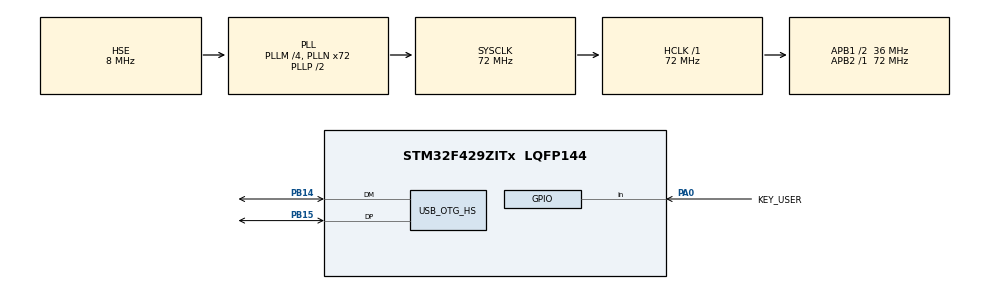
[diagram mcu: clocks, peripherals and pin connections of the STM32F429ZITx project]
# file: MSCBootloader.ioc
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Mcu.Family=STM32F4
Mcu.Name=STM32F429ZITx
Mcu.Package=LQFP144
NVIC.OTG_HS_IRQn=true\:0\:0\:false\:false\:true\:true
NVIC.PriorityGroup=NVIC_PRIORITYGROUP_4
PA0/WKUP.GPIO_Label=KEY_USER
PA0/WKUP.Signal=GPIO_Input
PA13.Mode=Serial_Wire
PA13.Signal=SYS_JTMS-SWDIO
PA14.Mode=Serial_Wire
PA14.Signal=SYS_JTCK-SWCLK
PB14.Mode=Device_Only_FS
PB14.Signal=USB_OTG_HS_DM
PB15.Mode=Device_Only_FS
PB15.Signal=USB_OTG_HS_DP
PH0/OSC_IN.Mode=HSE-External-Oscillator
PH0/OSC_IN.Signal=RCC_OSC_IN
PH1/OSC_OUT.Mode=HSE-External-Oscillator
PH1/OSC_OUT.Signal=RCC_OSC_OUT
ProjectManager.HeapSize=0x200
ProjectManager.StackSize=0x400
ProjectManager.TargetToolchain=SW4STM32
RCC.48MHZClocksFreq_Value=48000000
RCC.AHBFreq_Value=72000000
RCC.APB1CLKDivider=RCC_HCLK_DIV2
RCC.APB1Freq_Value=36000000
RCC.APB1TimFreq_Value=72000000
RCC.APB2Freq_Value=72000000
RCC.APB2TimFreq_Value=72000000
RCC.CortexFreq_Value=72000000
RCC.HCLKFreq_Value=72000000
RCC.HSE_VALUE=8000000
RCC.HSI_VALUE=16000000
RCC.LSE_VALUE=32768
RCC.PLLM=4
RCC.PLLN=72
RCC.PLLQ=3
RCC.SYSCLKFreq_VALUE=72000000
RCC.SYSCLKSource=RCC_SYSCLKSOURCE_PLLCLK
RCC.VCOOutputFreq_Value=144000000
USB_DEVICE.CLASS_NAME_HS=MSC
USB_DEVICE.VirtualMode-MSC_HS=Msc
USB_DEVICE.VirtualModeHS=Msc_HS
USB_OTG_HS.VirtualMode-Device_Only_FS=Device_Only_FS
VP_USB_DEVICE_VS_USB_DEVICE_MSC_HS.Mode=MSC_HS
board=custom

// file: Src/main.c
/**
  ******************************************************************************
  * @file           : main.c
  * @brief          : Main program body
  ******************************************************************************
  * This notice applies to any and all portions of this file
  * that are not between comment pairs USER CODE BEGIN and
  * USER CODE END. Other portions of this file, whether
  * inserted by the user or by software development tools
  * are owned by their respective copyright owners.
  *
  * Copyright (c) 2018 STMicroelectronics International N.V.
  * All rights reserved.
  *
  * Redistribution and use in source and binary forms, with or without
  * modification, are permitted, provided that the following conditions are met:
  *
  * 1. Redistribution of source code must retain the above copyright notice,
  *    this list of conditions and the following disclaimer.
  * 2. Redistributions in binary form must reproduce the above copyright notice,
  *    this list of conditions and the following disclaimer in the documentation
  *    and/or other materials provided with the distribution.
  * 3. Neither the name of STMicroelectronics nor the names of other
  *    contributors to this software may be used to endorse or promote products
  *    derived from this software without specific written permission.
  * 4. This software, including modifications and/or derivative works of this
  *    software, must execute solely and exclusively on microcontroller or
  *    microprocessor devices manufactured by or for STMicroelectronics.
  * 5. Redistribution and use of this software other than as permitted under
  *    this license is void and will automatically terminate your rights under
  *    this license.
  *
  * THIS SOFTWARE IS PROVIDED BY STMICROELECTRONICS AND CONTRIBUTORS "AS IS"
  * AND ANY EXPRESS, IMPLIED OR STATUTORY WARRANTIES, INCLUDING, BUT NOT
  * LIMITED TO, THE IMPLIED WARRANTIES OF MERCHANTABILITY, FITNESS FOR A
  * PARTICULAR PURPOSE AND NON-INFRINGEMENT OF THIRD PARTY INTELLECTUAL PROPERTY
  * RIGHTS ARE DISCLAIMED TO THE FULLEST EXTENT PERMITTED BY LAW. IN NO EVENT
  * SHALL STMICROELECTRONICS OR CONTRIBUTORS BE LIABLE FOR ANY DIRECT, INDIRECT,
  * INCIDENTAL, SPECIAL, EXEMPLARY, OR CONSEQUENTIAL DAMAGES (INCLUDING, BUT NOT
  * LIMITED TO, PROCUREMENT OF SUBSTITUTE GOODS OR SERVICES; LOSS OF USE, DATA,
  * OR PROFITS; OR BUSINESS INTERRUPTION) HOWEVER CAUSED AND ON ANY THEORY OF
  * LIABILITY, WHETHER IN CONTRACT, STRICT LIABILITY, OR TORT (INCLUDING
  * NEGLIGENCE OR OTHERWISE) ARISING IN ANY WAY OUT OF THE USE OF THIS SOFTWARE,
  * EVEN IF ADVISED OF THE POSSIBILITY OF SUCH DAMAGE.
  *
  ******************************************************************************
  */
#include "main.h"
#include "stm32f4xx_hal.h"
#include "usb_device.h"
#include "gpio.h"

/* USER CODE BEGIN Includes */
#include "bootloader.h"
#include "pfs.h"
/* USER CODE END Includes */

/* USER CODE BEGIN PV */
/* Private variables ---------------------------------------------------------*/

/* USER CODE END PV */

void SystemClock_Config(void);

/* USER CODE BEGIN PFP */
/* Private function prototypes -----------------------------------------------*/

extern void SCSI_ProcessReadCompleted(USBD_HandleTypeDef  *pdev, const uint8_t *buffer, uint16_t length);
extern void SCSI_ProcessWriteCompleted(USBD_HandleTypeDef  *pdev);

/* USER CODE END PFP */

int main(void)
{

  /* MCU Configuration----------------------------------------------------------*/

  /* Reset of all peripherals, Initializes the Flash interface and the Systick. */
  HAL_Init();

  /* Configure the system clock */
  SystemClock_Config();

  /* Initialize all configured peripherals */
  MX_GPIO_Init();
  /* USER CODE BEGIN 2 */
  bootloaderInit();
  MX_USB_DEVICE_Init();
  /* USER CODE END 2 */

  /* Infinite loop */
  /* USER CODE BEGIN WHILE */
  while (1)
  {
    pfsProcessLongOps();

  /* USER CODE END WHILE */

  }

}

void SystemClock_Config(void)
{

  RCC_OscInitTypeDef RCC_OscInitStruct;
  RCC_ClkInitTypeDef RCC_ClkInitStruct;

    /**Configure the main internal regulator output voltage
    */
  __HAL_RCC_PWR_CLK_ENABLE();

  __HAL_PWR_VOLTAGESCALING_CONFIG(PWR_REGULATOR_VOLTAGE_SCALE3);

    /**Initializes the CPU, AHB and APB busses clocks
    */
  RCC_OscInitStruct.OscillatorType = RCC_OSCILLATORTYPE_HSE;
  RCC_OscInitStruct.HSEState = RCC_HSE_ON;
  RCC_OscInitStruct.PLL.PLLState = RCC_PLL_ON;
  RCC_OscInitStruct.PLL.PLLSource = RCC_PLLSOURCE_HSE;
  RCC_OscInitStruct.PLL.PLLM = 4;
  RCC_OscInitStruct.PLL.PLLN = 72;
  RCC_OscInitStruct.PLL.PLLP = RCC_PLLP_DIV2;
  RCC_OscInitStruct.PLL.PLLQ = 3;
  if (HAL_RCC_OscConfig(&RCC_OscInitStruct) != HAL_OK)
  {
    _Error_Handler(__FILE__, __LINE__);
  }

    /**Initializes the CPU, AHB and APB busses clocks
    */
  RCC_ClkInitStruct.ClockType = RCC_CLOCKTYPE_HCLK|RCC_CLOCKTYPE_SYSCLK
                              |RCC_CLOCKTYPE_PCLK1|RCC_CLOCKTYPE_PCLK2;
  RCC_ClkInitStruct.SYSCLKSource = RCC_SYSCLKSOURCE_PLLCLK;
  RCC_ClkInitStruct.AHBCLKDivider = RCC_SYSCLK_DIV1;
  RCC_ClkInitStruct.APB1CLKDivider = RCC_HCLK_DIV2;
  RCC_ClkInitStruct.APB2CLKDivider = RCC_HCLK_DIV1;

  if (HAL_RCC_ClockConfig(&RCC_ClkInitStruct, FLASH_LATENCY_2) != HAL_OK)
  {
    _Error_Handler(__FILE__, __LINE__);
  }

    /**Configure the Systick interrupt time
    */
  HAL_SYSTICK_Config(HAL_RCC_GetHCLKFreq()/1000);

    /**Configure the Systick
    */
  HAL_SYSTICK_CLKSourceConfig(SYSTICK_CLKSOURCE_HCLK);

  /* SysTick_IRQn interrupt configuration */
  HAL_NVIC_SetPriority(SysTick_IRQn, 0, 0);
}

/* USER CODE BEGIN 4 */

bool bootloaderIsFirmwarePresent(void)
{
  uint32_t *pEStack = (uint32_t *)BOOTLOADER_FW_AREA_START;
  uint32_t estack = *pEStack;

  if ((estack >= 0x20000000) && (estack <= (0x20000000 + (192 * 1024)))) {
    return true;
  }

  return false;
}

bool bootloaderIsManualStartRequired(void)
{
  if (HAL_GPIO_ReadPin(KEY_USER_GPIO_Port, KEY_USER_Pin) == GPIO_PIN_SET) {
    return true;
  }

  return false;
}

void bootloaderRunFirmware(void)
{
  typedef void (*pFunction)(void);
  pFunction Jump_To_Application;
  volatile uint32_t *vectorsTable = (volatile uint32_t *)BOOTLOADER_FW_AREA_START;

  uint32_t JumpAddress = vectorsTable[1];
  Jump_To_Application = (pFunction) JumpAddress;

  /* Initialize user application's Stack Pointer */
  __set_MSP(vectorsTable[0]);
  Jump_To_Application();
}

static uint32_t GetSector(uint32_t Address);
static uint32_t GetSectorSize(uint32_t Sector);

bool bootloaderPrepareFimrwareArea(void)
{
  HAL_FLASH_Unlock();

  uint32_t count = BOOTLOADER_FW_AREA_SIZE / sizeof(uint32_t);
  uint32_t *p = (uint32_t *)BOOTLOADER_FW_AREA_START;

  for (uint32_t i = 0 ; i < count; i++) {
    if (*p++ != 0) {
      FLASH_EraseInitTypeDef EraseInitStruct;
      uint32_t FirstSector = 0, NbOfSectors = 0;
      uint32_t Address = 0, SECTORError = 0;

      /* Get the 1st sector to erase */
      FirstSector = GetSector(BOOTLOADER_FW_AREA_START);
      /* Get the number of sector to erase from 1st sector*/
      NbOfSectors = GetSector(BOOTLOADER_FW_AREA_START + BOOTLOADER_FW_AREA_SIZE - 1) - FirstSector + 1;
      EraseInitStruct.TypeErase     = FLASH_TYPEERASE_SECTORS;
      EraseInitStruct.VoltageRange  = FLASH_VOLTAGE_RANGE_3;
      EraseInitStruct.Sector        = FirstSector;
      EraseInitStruct.NbSectors     = NbOfSectors;

      if (HAL_FLASHEx_Erase(&EraseInitStruct, &SECTORError) != HAL_OK) {
        while (1) {
          __NOP();
        }
      }

      break;
    }
  }

  return true;
}

void pfsFileReadCompletedCallback(void *context, const uint8_t *buffer, uint16_t length)
{
  SCSI_ProcessReadCompleted((USBD_HandleTypeDef *)context, buffer, length);
}

void pfsFileWriteCompletedCallback(void *context)
{
  SCSI_ProcessWriteCompleted((USBD_HandleTypeDef *)context);
}

bool bootloaderWriteFirmware(const uint8_t *buffer, uint32_t address, uint32_t count)
{
  for (uint32_t itemIndex = 0u; itemIndex < count; itemIndex += 4u) {
    const uint32_t *value = (const uint32_t *)&buffer[itemIndex];

    if (HAL_FLASH_Program(FLASH_TYPEPROGRAM_WORD, address + itemIndex, (*value)) != HAL_OK) {
      return false;
    }
  }

  return true;
}

#define ADDR_FLASH_SECTOR_0     ((uint32_t)0x08000000) /* Base @ of Sector 0, 16 Kbytes */
#define ADDR_FLASH_SECTOR_1     ((uint32_t)0x08004000) /* Base @ of Sector 1, 16 Kbytes */
#define ADDR_FLASH_SECTOR_2     ((uint32_t)0x08008000) /* Base @ of Sector 2, 16 Kbytes */
#define ADDR_FLASH_SECTOR_3     ((uint32_t)0x0800C000) /* Base @ of Sector 3, 16 Kbytes */
#define ADDR_FLASH_SECTOR_4     ((uint32_t)0x08010000) /* Base @ of Sector 4, 64 Kbytes */
#define ADDR_FLASH_SECTOR_5     ((uint32_t)0x08020000) /* Base @ of Sector 5, 128 Kbytes */
#define ADDR_FLASH_SECTOR_6     ((uint32_t)0x08040000) /* Base @ of Sector 6, 128 Kbytes */
#define ADDR_FLASH_SECTOR_7     ((uint32_t)0x08060000) /* Base @ of Sector 7, 128 Kbytes */
#define ADDR_FLASH_SECTOR_8     ((uint32_t)0x08080000) /* Base @ of Sector 8, 128 Kbytes */
#define ADDR_FLASH_SECTOR_9     ((uint32_t)0x080A0000) /* Base @ of Sector 9, 128 Kbytes */
#define ADDR_FLASH_SECTOR_10    ((uint32_t)0x080C0000) /* Base @ of Sector 10, 128 Kbytes */
#define ADDR_FLASH_SECTOR_11    ((uint32_t)0x080E0000) /* Base @ of Sector 11, 128 Kbytes */

/* Base address of the Flash sectors Bank 2 */
#define ADDR_FLASH_SECTOR_12     ((uint32_t)0x08100000) /* Base @ of Sector 0, 16 Kbytes */
#define ADDR_FLASH_SECTOR_13     ((uint32_t)0x08104000) /* Base @ of Sector 1, 16 Kbytes */
#define ADDR_FLASH_SECTOR_14     ((uint32_t)0x08108000) /* Base @ of Sector 2, 16 Kbytes */
#define ADDR_FLASH_SECTOR_15     ((uint32_t)0x0810C000) /* Base @ of Sector 3, 16 Kbytes */
#define ADDR_FLASH_SECTOR_16     ((uint32_t)0x08110000) /* Base @ of Sector 4, 64 Kbytes */
#define ADDR_FLASH_SECTOR_17     ((uint32_t)0x08120000) /* Base @ of Sector 5, 128 Kbytes */
#define ADDR_FLASH_SECTOR_18     ((uint32_t)0x08140000) /* Base @ of Sector 6, 128 Kbytes */
#define ADDR_FLASH_SECTOR_19     ((uint32_t)0x08160000) /* Base @ of Sector 7, 128 Kbytes */
#define ADDR_FLASH_SECTOR_20     ((uint32_t)0x08180000) /* Base @ of Sector 8, 128 Kbytes  */
#define ADDR_FLASH_SECTOR_21     ((uint32_t)0x081A0000) /* Base @ of Sector 9, 128 Kbytes  */
#define ADDR_FLASH_SECTOR_22     ((uint32_t)0x081C0000) /* Base @ of Sector 10, 128 Kbytes */
#define ADDR_FLASH_SECTOR_23     ((uint32_t)0x081E0000) /* Base @ of Sector 11, 128 Kbytes */

/**
  * @brief  Gets the sector of a given address
  * @param  None
  * @retval The sector of a given address
  */
static uint32_t GetSector(uint32_t Address)
{
  uint32_t sector = 0;

  if ((Address < ADDR_FLASH_SECTOR_1) && (Address >= ADDR_FLASH_SECTOR_0)) {
    sector = FLASH_SECTOR_0;
  } else if ((Address < ADDR_FLASH_SECTOR_2) && (Address >= ADDR_FLASH_SECTOR_1)) {
    sector = FLASH_SECTOR_1;
  } else if ((Address < ADDR_FLASH_SECTOR_3) && (Address >= ADDR_FLASH_SECTOR_2)) {
    sector = FLASH_SECTOR_2;
  } else if ((Address < ADDR_FLASH_SECTOR_4) && (Address >= ADDR_FLASH_SECTOR_3)) {
    sector = FLASH_SECTOR_3;
  } else if ((Address < ADDR_FLASH_SECTOR_5) && (Address >= ADDR_FLASH_SECTOR_4)) {
    sector = FLASH_SECTOR_4;
  } else if ((Address < ADDR_FLASH_SECTOR_6) && (Address >= ADDR_FLASH_SECTOR_5)) {
    sector = FLASH_SECTOR_5;
  } else if ((Address < ADDR_FLASH_SECTOR_7) && (Address >= ADDR_FLASH_SECTOR_6)) {
    sector = FLASH_SECTOR_6;
  } else if ((Address < ADDR_FLASH_SECTOR_8) && (Address >= ADDR_FLASH_SECTOR_7)) {
    sector = FLASH_SECTOR_7;
  } else if ((Address < ADDR_FLASH_SECTOR_9) && (Address >= ADDR_FLASH_SECTOR_8)) {
    sector = FLASH_SECTOR_8;
  } else if ((Address < ADDR_FLASH_SECTOR_10) && (Address >= ADDR_FLASH_SECTOR_9)) {
    sector = FLASH_SECTOR_9;
  } else if ((Address < ADDR_FLASH_SECTOR_11) && (Address >= ADDR_FLASH_SECTOR_10)) {
    sector = FLASH_SECTOR_10;
  } else if ((Address < ADDR_FLASH_SECTOR_12) && (Address >= ADDR_FLASH_SECTOR_11)) {
    sector = FLASH_SECTOR_11;
  } else if ((Address < ADDR_FLASH_SECTOR_13) && (Address >= ADDR_FLASH_SECTOR_12)) {
    sector = FLASH_SECTOR_12;
  } else if ((Address < ADDR_FLASH_SECTOR_14) && (Address >= ADDR_FLASH_SECTOR_13)) {
    sector = FLASH_SECTOR_13;
  } else if ((Address < ADDR_FLASH_SECTOR_15) && (Address >= ADDR_FLASH_SECTOR_14)) {
    sector = FLASH_SECTOR_14;
  } else if ((Address < ADDR_FLASH_SECTOR_16) && (Address >= ADDR_FLASH_SECTOR_15)) {
    sector = FLASH_SECTOR_15;
  } else if ((Address < ADDR_FLASH_SECTOR_17) && (Address >= ADDR_FLASH_SECTOR_16)) {
    sector = FLASH_SECTOR_16;
  } else if ((Address < ADDR_FLASH_SECTOR_18) && (Address >= ADDR_FLASH_SECTOR_17)) {
    sector = FLASH_SECTOR_17;
  } else if ((Address < ADDR_FLASH_SECTOR_19) && (Address >= ADDR_FLASH_SECTOR_18)) {
    sector = FLASH_SECTOR_18;
  } else if ((Address < ADDR_FLASH_SECTOR_20) && (Address >= ADDR_FLASH_SECTOR_19)) {
    sector = FLASH_SECTOR_19;
  } else if ((Address < ADDR_FLASH_SECTOR_21) && (Address >= ADDR_FLASH_SECTOR_20)) {
    sector = FLASH_SECTOR_20;
  } else if ((Address < ADDR_FLASH_SECTOR_22) && (Address >= ADDR_FLASH_SECTOR_21)) {
    sector = FLASH_SECTOR_21;
  } else if ((Address < ADDR_FLASH_SECTOR_23) && (Address >= ADDR_FLASH_SECTOR_22)) {
    sector = FLASH_SECTOR_22;
  } else { /* (Address < FLASH_END_ADDR) && (Address >= ADDR_FLASH_SECTOR_23) */
    sector = FLASH_SECTOR_23;
  }

  return sector;
}

/**
  * @brief  Gets sector Size
  * @param  None
  * @retval The size of a given sector
  */
static uint32_t GetSectorSize(uint32_t Sector)
{
  uint32_t sectorsize = 0x00;

  if ((Sector == FLASH_SECTOR_0) || (Sector == FLASH_SECTOR_1) || (Sector == FLASH_SECTOR_2) || \
      (Sector == FLASH_SECTOR_3) || (Sector == FLASH_SECTOR_12) || (Sector == FLASH_SECTOR_13) || \
      (Sector == FLASH_SECTOR_14) || (Sector == FLASH_SECTOR_15)) {
    sectorsize = 16 * 1024;
  } else if ((Sector == FLASH_SECTOR_4) || (Sector == FLASH_SECTOR_16)) {
    sectorsize = 64 * 1024;
  } else {
    sectorsize = 128 * 1024;
  }

  return sectorsize;
}

/* USER CODE END 4 */

void _Error_Handler(char *file, int line)
{
  while(1)
  {
  }
}

/************************ (C) COPYRIGHT STMicroelectronics *****END OF FILE****/
